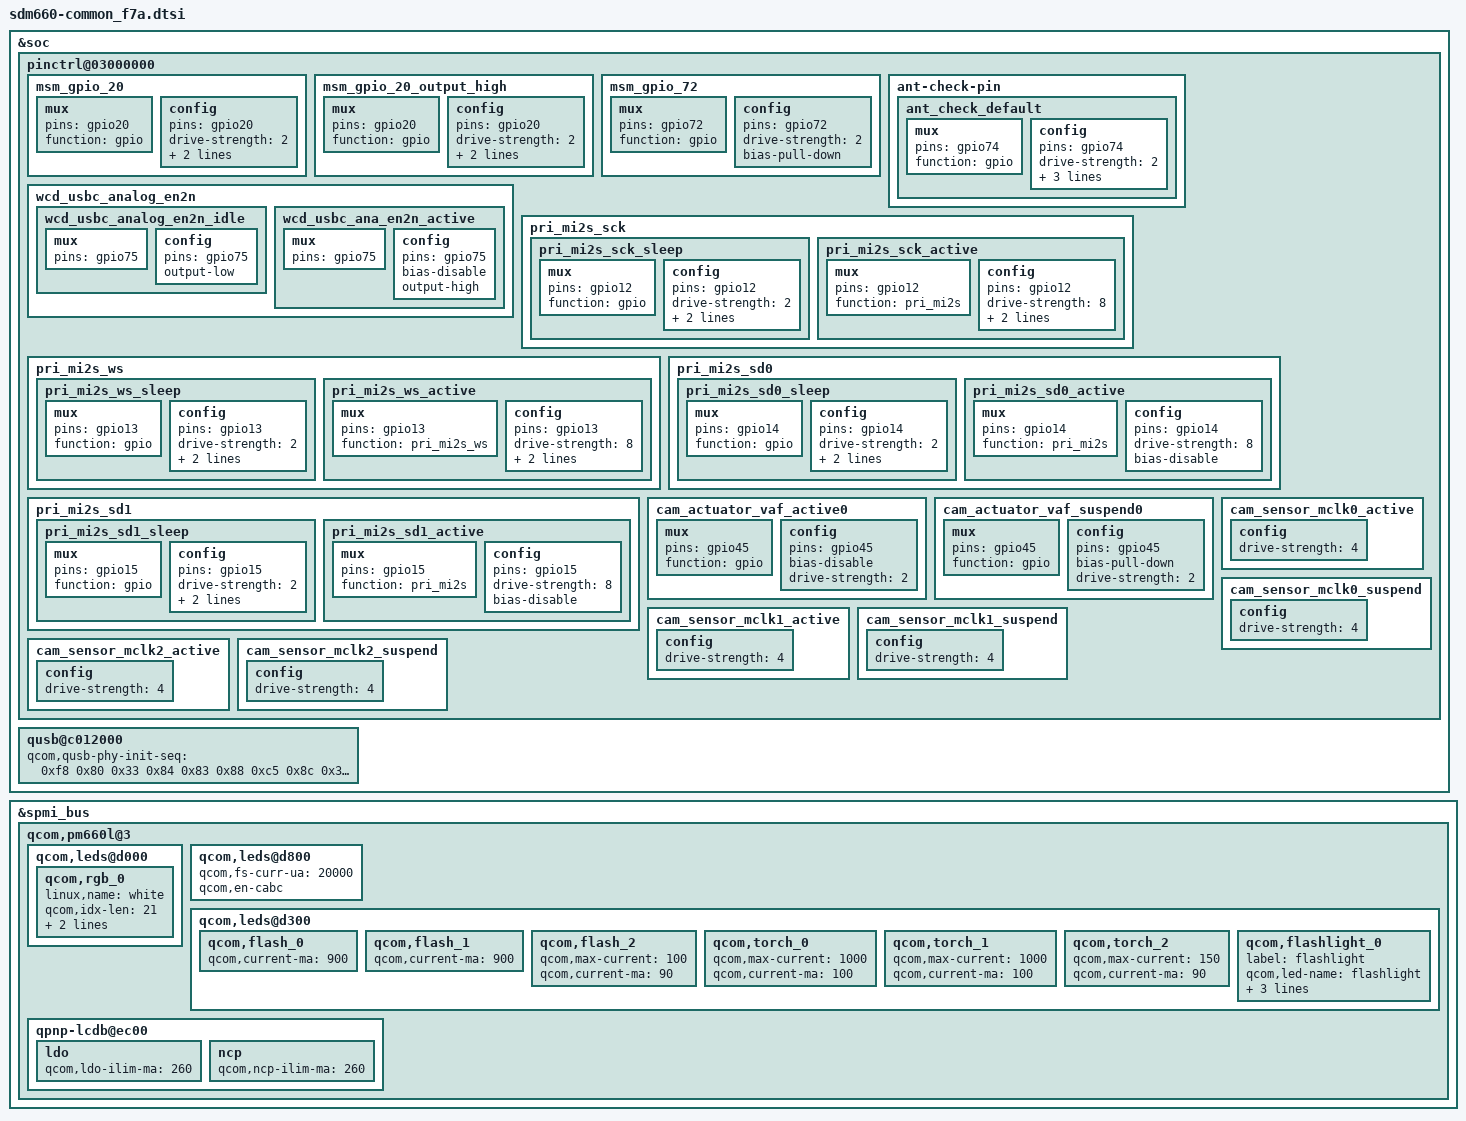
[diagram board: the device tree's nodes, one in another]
/* Copyright (c) 2016-2017, The Linux Foundation. All rights reserved.
 * Copyright (C) 2019 XiaoMi, Inc.
 *
 * This program is free software; you can redistribute it and/or modify
 * it under the terms of the GNU General Public License version 2 and
 * only version 2 as published by the Free Software Foundation.
 *
 * This program is distributed in the hope that it will be useful,
 * but WITHOUT ANY WARRANTY; without even the implied warranty of
 * MERCHANTABILITY or FITNESS FOR A PARTICULAR PURPOSE.  See the
 * GNU General Public License for more details.
 */

#include "sdm660-common.dtsi"

&soc {
	pinctrl@03000000 {
		msm_gpio_20:msm_gpio_20 {
			mux{
				pins="gpio20";
				function= "gpio";
			};
			config {
				pins= "gpio20";
				drive-strength = <2>;
				bias-disable;
				output-low;
			};
		};

		msm_gpio_20_output_high:msm_gpio_20_output_high {
			mux {
			pins = "gpio20";
			function = "gpio";

		};
			config{
				pins = "gpio20";
				drive-strength = <2>;
				bias-disable;
				output-high;
			};
		};

		msm_gpio_72:msm_gpio_72{
			mux{
				pins = "gpio72";
				function = "gpio";
			};
			config{
				pins = "gpio72";
				drive-strength=<2>;
				bias-pull-down;
			};
		};

		ant-check-pin {
			ant_check_default: ant_check_default {
				mux {
					pins = "gpio74";
					function = "gpio";
				};
				config {
					pins = "gpio74";
					drive-strength = <2>;
					bias-disable;
					input-enable;
					input-debounce = <5000>;
				};
			};
		};

		wcd_usbc_analog_en2n {
			wcd_usbc_analog_en2n_idle {
				mux {
					pins = "gpio75";
				};
				config {
					pins = "gpio75";
					/delete-property/ output-high;
					output-low;
				};
			};

			wcd_usbc_ana_en2n_active {
				mux {
					pins = "gpio75";
				};
				config {
					pins = "gpio75";
					/delete-property/ bias-pull-down;
					/delete-property/ output-low;
					bias-disable;
					output-high;
				};
			};
		};

		/* add pri_mi2s for smartpa */
		pri_mi2s_sck {
			pri_mi2s_sck_sleep: pri_mi2s_sck_sleep {
				mux {
					pins = "gpio12";
					function = "gpio";
				};

				config {
					pins = "gpio12";
					drive-strength = <2>;   /* 2 mA */
					bias-pull-down;         /* PULL DOWN */
					input-enable;
				};
			};

			pri_mi2s_sck_active: pri_mi2s_sck_active {
				mux {
					pins = "gpio12";
					function = "pri_mi2s";
				};

				config {
					pins = "gpio12";
					drive-strength = <8>;   /* 8 mA */
					bias-disable;           /* NO PULL */
					output-high;
				};
			};
		};

		pri_mi2s_ws {
			pri_mi2s_ws_sleep: pri_mi2s_ws_sleep {
				mux {
					pins = "gpio13";
					function = "gpio";
				};

				config {
					pins = "gpio13";
					drive-strength = <2>;   /* 2 mA */
					bias-pull-down;         /* PULL DOWN */
					input-enable;
				};
			};

			pri_mi2s_ws_active: pri_mi2s_ws_active {
				mux {
					pins = "gpio13";
					function = "pri_mi2s_ws";
				};

				config {
					pins = "gpio13";
					drive-strength = <8>;   /* 8 mA */
					bias-disable;           /* NO PULL */
					output-high;
				};
			};
		};

		pri_mi2s_sd0 {
			pri_mi2s_sd0_sleep: pri_mi2s_sd0_sleep {
				mux {
					pins = "gpio14";
					function = "gpio";
				};

				config {
					pins = "gpio14";
					drive-strength = <2>;   /* 2 mA */
					bias-pull-down;         /* PULL DOWN */
					input-enable;
				};
			};

			pri_mi2s_sd0_active: pri_mi2s_sd0_active {
				mux {
					pins = "gpio14";
					function = "pri_mi2s";
				};

				config {
					pins = "gpio14";
					drive-strength = <8>;   /* 8 mA */
					bias-disable;           /* NO PULL */
				};
			};
		};

		pri_mi2s_sd1 {
			pri_mi2s_sd1_sleep: pri_mi2s_sd1_sleep {
				mux {
					pins = "gpio15";
					function = "gpio";
				};

				config {
					pins = "gpio15";
					drive-strength = <2>;   /* 2 mA */
					bias-pull-down;         /* PULL DOWN */
					input-enable;
				};
			};

			pri_mi2s_sd1_active: pri_mi2s_sd1_active {
				mux {
					pins = "gpio15";
					function = "pri_mi2s";
				};

				config {
					pins = "gpio15";
					drive-strength = <8>;   /* 8 mA */
					bias-disable;           /* NO PULL */
				};
			};
		};

		cam_actuator_vaf_active0: cam_actuator_vaf_active0 {
			/* ACTUATOR POWER */
			mux {
				pins = "gpio45";
				function = "gpio";
			};

			config {
				pins = "gpio45";
				bias-disable; /* No PULL */
				drive-strength = <2>; /* 2 MA */
			};
		};

		cam_actuator_vaf_suspend0: cam_actuator_vaf_suspend0 {
			/* ACTUATOR POWER */
			mux {
				pins = "gpio45";
				function = "gpio";
			};

			config {
				pins = "gpio45";
				bias-pull-down; /* PULL DOWN */
				drive-strength = <2>; /* 2 MA */
			};
		};

		cam_sensor_mclk0_active {
			config {
				drive-strength = <4>; /* 2 MA */
			};
		};

		cam_sensor_mclk0_suspend {
			config {
				drive-strength = <4>; /* 2 MA */
			};
		};

		cam_sensor_mclk1_active {
			config {
				drive-strength = <4>; /* 2 MA */
			};
		};

		cam_sensor_mclk1_suspend {
			config {
				drive-strength = <4>; /* 2 MA */
			};
		};

		cam_sensor_mclk2_active {
			config {
				drive-strength = <4>; /* 2 MA */
			};
		};

		cam_sensor_mclk2_suspend {
			config {
				drive-strength = <4>; /* 2 MA */
			};
		};
	};

	qusb@c012000 {
		qcom,qusb-phy-init-seq = <0xf8 0x80
					0x33 0x84
					0x83 0x88
					0xc5 0x8c
					0x30 0x08
					0x79 0x0c
					0x21 0x10
					0x14 0x9c
					0x9f 0x1c
					0x00 0x18>;
	};

};

&spmi_bus {
	qcom,pm660l@3 {
		qcom,leds@d000 {
			qcom,rgb_0 {
				linux,name = "white";
				qcom,idx-len = <21>;
				qcom,duty-pcts =
					[00 19 32 4B 64
					 64 4B 32 19 00];
			};
		};

		qcom,leds@d800 {
			qcom,fs-curr-ua = <20000>;
			qcom,en-cabc;
			/delete-property/ qcom,auto-calibration-enable;
		};

		qcom,leds@d300 {
			qcom,flash_0 {
				qcom,current-ma = <900>;
			};

			qcom,flash_1 {
				qcom,current-ma = <900>;
			};

			qcom,flash_2 {
				qcom,max-current = <100>;
				qcom,current-ma = <90>;
			};

			qcom,torch_0 {
				qcom,max-current = <1000>;
				qcom,current-ma = <100>;
			};

			qcom,torch_1 {
				qcom,max-current = <1000>;
				qcom,current-ma = <100>;
			};

			qcom,torch_2 {
				qcom,max-current = <150>;
				qcom,current-ma = <90>;
			};

			qcom,flashlight_0 {
				label = "flashlight";
				qcom,led-name = "flashlight";
				qcom,torch-name = "led:torch_0", "led:torch_1";
				qcom,switch-name = "led:switch_0";
				qcom,id = <0>;
			};
		};

		qpnp-lcdb@ec00 {
			ldo {
				qcom,ldo-ilim-ma = <260>;
			};

			ncp {
				qcom,ncp-ilim-ma = <260>;
			};
		};
	};
};
